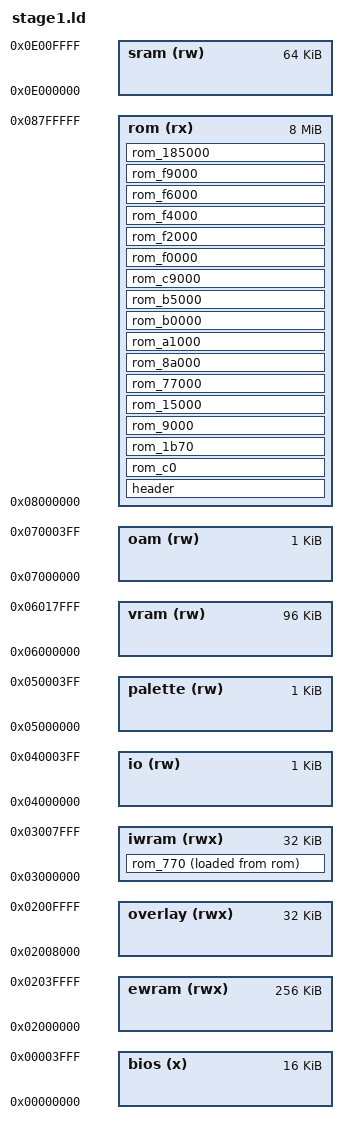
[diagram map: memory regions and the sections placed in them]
MEMORY {
	bios	(x)	: ORIGIN = 0x00000000, LENGTH = 16K
	ewram	(rwx)	: ORIGIN = 0x02000000, LENGTH = 256K
	overlay (rwx)	: ORIGIN = 0x02008000, LENGTH = 32K
	iwram	(rwx)	: ORIGIN = 0x03000000, LENGTH = 32K
	io	(rw)	: ORIGIN = 0x04000000, LENGTH = 1K
	palette	(rw)	: ORIGIN = 0x05000000, LENGTH = 1K
	vram	(rw)	: ORIGIN = 0x06000000, LENGTH = 96K
	oam	(rw)	: ORIGIN = 0x07000000, LENGTH = 1K
	rom	(rx)	: ORIGIN = 0x08000000, LENGTH = 8M
	sram	(rw)	: ORIGIN = 0x0E000000, LENGTH = 64K
}

INCLUDE "linker/symbols/wram.sym"
INCLUDE "linker/symbols/message.sym"
INCLUDE "linker/symbols/file_table.sym"
INCLUDE "linker/symbols/event.sym"

SECTIONS {
	header : {
		build/usa/obj/src/core/header/rom_header.o(.text)
	} > rom

	rom_c0 : {
		build/usa/obj/exports/core/startup/exports.o(.text)
		build/usa/obj/src/core/startup/crt0.o(.text)
	} > rom

	rom_770 : {
		build/usa/obj/src/core/ramlib.o(.text)
	} > iwram AT > rom

	rom_1b70 : {
		build/usa/obj/src/core/runtime/decompress/lz1.o(.text)
		build/usa/obj/src/core/runtime/render/blit_fade_rom.o(.text)
		build/usa/obj/src/core/runtime/render/blit_fade_alt.o(.text)
		build/usa/obj/src/core/runtime/decompress/lz16.o(.text)
		build/usa/obj/src/core/runtime/math/gcc_div.o(.text)
		build/usa/obj/src/core/runtime/math/sin.o(.text)
		build/usa/obj/src/core/runtime/decompress/lz_rom.o(.text)
		build/usa/obj/src/core/runtime/decompress/lz2.o(.text)
		build/usa/obj/src/core/runtime/fixup_ram_code.o(.text)
		build/usa/obj/src/core/runtime/memory/free.o(.text)
		build/usa/obj/src/core/runtime/main.o(.text)
		build/usa/obj/src/core/runtime/intr/intr.o(.text)
		build/usa/obj/src/core/runtime/video.o(.text)
		build/usa/obj/src/core/runtime/task.o(.text)
		build/usa/obj/src/core/runtime/random.o(.text)
		build/usa/obj/src/core/runtime/math/math.o(.text)
		build/usa/obj/src/core/runtime/sprite/palette.o(.text)
		build/usa/obj/src/core/runtime/memory/alloc.o(.text)
		build/usa/obj/src/core/runtime/math/matrix.o(.text)
		build/usa/obj/src/core/runtime/math/vector.o(.text)
		build/usa/obj/src/core/runtime/decompress/lz.o(.text)
		build/usa/obj/src/core/runtime/render/blit_fade.o(.text)
		build/usa/obj/src/core/runtime/save.o(.text)
		build/usa/obj/src/core/runtime/serial.o(.text)
		build/usa/obj/src/core/runtime/other/sub_8006864.o(.text)
		build/usa/obj/src/lib/agb_flash/agb_flash.o(.text)
		build/usa/obj/src/lib/agb_flash/agb_flash_mx.o(.text)
		build/usa/obj/src/lib/agb_flash/agb_flash_verify.o(.text)
		build/usa/obj/src/lib/agb_flash/agb_flash_at.o(.text)
		build/usa/obj/src/lib/call_via.o(.text)

		build/usa/obj/src/core/runtime/intr/intr.o(.rodata)
		build/usa/obj/data/core/runtime/rom_45e8_c_c_c_c_c.o(.rodata)
		build/usa/obj/data/core/runtime/rom_49a8_c_c_c_c_c.o(.rodata)
		build/usa/obj/src/core/runtime/save.o(.rodata)
		build/usa/obj/src/lib/agb_flash/agb_flash_data.o(.rodata)

		. += 0x1000;
	} > rom

	rom_9000 : ALIGN(0x1000) {
		build/usa/obj/exports/field_engine/exports.o(.text)
		build/usa/obj/src/field_engine/sprite/draw_sprite.o(.text)
		build/usa/obj/src/field_engine/engine/unpack_tilemap.o(.text)
		build/usa/obj/src/field_engine/sprite/rom_a418.o(.text)
		build/usa/obj/src/field_engine/decompress/sprite_lz.o(.text)
		build/usa/obj/src/field_engine/sprite/sprite.o(.text)
		build/usa/obj/src/field_engine/actor/actor.o(.text)
		build/usa/obj/src/field_engine/actor/actor_script.o(.text)
		build/usa/obj/src/field_engine/actor/player.o(.text)
		build/usa/obj/src/field_engine/field/map_data.o(.text)
		build/usa/obj/src/field_engine/engine/sprite_test.o(.text)

		build/usa/obj/src/field_engine/sprite/sprite.o(.rodata.rom_b798_c_c)
		build/usa/obj/src/field_engine/sprite/sprite.o(.rodata.rom_b074_c)
		build/usa/obj/src/field_engine/sprite/sprite.o(.rodata)
		build/usa/obj/src/field_engine/sprite/sprite.o(.rodata.rom_be70_c)
		build/usa/obj/src/field_engine/actor/actor.o(.rodata)
		build/usa/obj/src/field_engine/actor/actor_script.o(.rodata)
		build/usa/obj/data/field_engine/rom_d654_c_c_c.o(.rodata)
		build/usa/obj/src/field_engine/actor/player.o(.rodata)
		build/usa/obj/src/field_engine/field/map_data.o(.rodata.rom_108e4)
		build/usa/obj/src/field_engine/field/map_data.o(.rodata.rom_11ce0_c_c)
		build/usa/obj/src/field_engine/engine/sprite_test.o(.rodata.rom_1219c_c_c)
		build/usa/obj/data/field_engine/rom_c004_c_c_c.o(.rodata)
		build/usa/obj/data/field_engine/rom_13624.o(.rodata)
		build/usa/obj/src/field_engine/field/map_data.o(.rodata.rom_f9cc_c)
	} > rom

	rom_15000 : ALIGN(0x1000) {
		build/usa/obj/exports/ui/exports.o(.text)
		build/usa/obj/src/ui/decompress/huffman.o(.text)
		build/usa/obj/src/ui/decompress/icon.o(.text)
		build/usa/obj/src/ui/window.o(.text)
		build/usa/obj/src/ui/ui.o(.text)
		build/usa/obj/src/ui/icon.o(.text)
		build/usa/obj/src/ui/menu.o(.text)
		build/usa/obj/src/ui/text.o(.text)
		build/usa/obj/src/ui/save_menu.o(.text)
		build/usa/obj/src/ui/menus/menu_bars.o(.text)
		build/usa/obj/src/ui/menus/debug_warp_menu.o(.text)
		build/usa/obj/src/ui/menus/debug_flag_editor.o(.text)
		build/usa/obj/src/ui/debug/icon_test.o(.text)

		build/usa/obj/data/ui/rom_29910.o(.rodata)
		build/usa/obj/src/ui/icon.o(.rodata)
		build/usa/obj/data/ui/rom_310a4.o(.rodata)
		build/usa/obj/src/ui/save_menu.o(.rodata.rom_22a7c)
		build/usa/obj/data/ui/rom_317e4.o(.rodata)
		build/usa/obj/src/ui/ui.o(.rodata.rom_178b0)
		build/usa/obj/data/ui/rom_32224.o(.rodata)
		build/usa/obj/src/ui/ui.o(.rodata.rom_17e88_c)
		build/usa/obj/src/ui/ui.o(.rodata.rom_1908c_c_c)
		build/usa/obj/src/ui/menu.o(.rodata.rom_1aeec_c_c)
		build/usa/obj/data/ui/rom_346f8.o(.rodata)
		build/usa/obj/src/ui/menu.o(.rodata.rom_1a66c_c_c)
		build/usa/obj/src/ui/menu.o(.rodata.rom_1ca1c_c_c_c)
		build/usa/obj/data/ui/rom_367e4.o(.rodata)
		build/usa/obj/src/ui/text.o(.rodata)
		build/usa/obj/src/ui/save_menu.o(.rodata.rom_20198_c_c_c_c_c)
		build/usa/obj/src/ui/save_menu.o(.rodata.rom_23178_c_c)
		build/usa/obj/generated/strings/strings.o(.rodata)
		build/usa/obj/data/ui/rom_15e8c_c_c_c.o(.rodata)
		build/usa/obj/data/ui/rom_73812.o(.rodata)
		build/usa/obj/src/ui/save_menu.o(.rodata.rom_1fe2c)
		build/usa/obj/data/ui/rom_73864.o(.rodata)

		. += 0x3000;
	} > rom

	rom_77000 : ALIGN(0x1000) {
		build/usa/obj/exports/rpg/exports.o(.text)
		build/usa/obj/src/rpg/party.o(.text)
		build/usa/obj/src/rpg/get_unit.o(.text)
		build/usa/obj/src/rpg/party.o(.text.party_2)
		build/usa/obj/src/rpg/item.o(.text)
		build/usa/obj/src/rpg/move.o(.text)
		build/usa/obj/src/rpg/pc.o(.text)
		build/usa/obj/src/rpg/flags.o(.text)
		build/usa/obj/src/rpg/pc.o(.text.rpg_pc_2)
		build/usa/obj/src/rpg/summon.o(.text)
		build/usa/obj/src/rpg/random.o(.text)
		build/usa/obj/src/rpg/pc.o(.text.rpg_pc_3)
		build/usa/obj/src/rpg/djinni.o(.text)
		build/usa/obj/src/rpg/pc.o(.text.rpg_pc_4)

		build/usa/obj/src/rpg/party.o(.rodata)
		build/usa/obj/data/rpg/rom_79008_c.o(.rodata)
		build/usa/obj/data/rpg/rom_78a8c_c_c.o(.rodata)
		build/usa/obj/data/rpg/rom_78ee8_c.o(.rodata)
		build/usa/obj/data/rpg/rom_78414_c_c_c_c.o(.rodata)
		build/usa/obj/data/rpg/rom_78b9c_c.o(.rodata)
		build/usa/obj/data/rpg/rom_80ec8.o(.rodata)
		build/usa/obj/data/rpg/rom_78ed8_c.o(.rodata)
		build/usa/obj/src/rpg/djinni.o(.rodata)
	} > rom

	rom_8a000 : ALIGN(0x1000) {
		build/usa/obj/exports/field/exports.o(.text)
		build/usa/obj/src/field/map_load.o(.text)
		build/usa/obj/src/field/room_load.o(.text)
		build/usa/obj/src/field/map_actor.o(.text)
		build/usa/obj/src/field/field.o(.text)
		build/usa/obj/src/field/map.o(.text)
		build/usa/obj/src/field/cutscene.o(.text)
		build/usa/obj/src/field/map_actor.o(.text.map_actor_2)
		build/usa/obj/src/field/map_actor_api.o(.text)
		build/usa/obj/src/field/weather.o(.text)
		build/usa/obj/src/field/djinni.o(.text)
		build/usa/obj/src/field/field_move.o(.text)
		build/usa/obj/src/field/weather.o(.text.weather_2)
		build/usa/obj/src/field/actor_move.o(.text)
		build/usa/obj/src/field/psynergy.o(.text)
		build/usa/obj/src/field/moves/mind_read.o(.text)
		build/usa/obj/src/field/psynergy.o(.text.psynergy_2)
		build/usa/obj/src/field/moves/move.o(.text)
		build/usa/obj/src/field/moves/reveal.o(.text)
		build/usa/obj/src/field/moves/growth.o(.text)
		build/usa/obj/src/field/moves/lift.o(.text)
		build/usa/obj/src/field/moves/force.o(.text)
		build/usa/obj/src/field/moves/frost.o(.text)
		build/usa/obj/src/field/moves/ply.o(.text)
		build/usa/obj/src/field/moves/cloak.o(.text)
		build/usa/obj/src/field/moves/douse.o(.text)
		build/usa/obj/src/field/moves/carry.o(.text)
		build/usa/obj/src/field/moves/whirlwind.o(.text)
		build/usa/obj/src/field/moves/halt.o(.text)
		build/usa/obj/src/field/moves/catch.o(.text)
		build/usa/obj/src/field/moves/retreat.o(.text)
		build/usa/obj/src/field/moves/avoid.o(.text)
		build/usa/obj/src/field/field_effect.o(.text)
		build/usa/obj/src/field/transition.o(.text)

		build/usa/obj/src/field/actor_move.o(.rodata)
		build/usa/obj/src/field/field_effect.o(.rodata)
		build/usa/obj/data/field/rom_8ace0_c.o(.rodata)
		build/usa/obj/src/field/map.o(.rodata)
		build/usa/obj/data/field/rom_9259c_c.o(.rodata)
		build/usa/obj/src/field/map_actor.o(.rodata.rom_92950_c_c_c_c)
		build/usa/obj/src/field/weather.o(.rodata)
		build/usa/obj/data/field/rom_9f0b0.o(.rodata)
		build/usa/obj/src/field/moves/move.o(.rodata)
		build/usa/obj/src/field/moves/avoid.o(.rodata)
		build/usa/obj/data/field/rom_9bb64_c_c.o(.rodata)
		build/usa/obj/data/field/rom_8a5f8_c.o(.rodata)
		build/usa/obj/data/field/rom_8b674_c_c_c.o(.rodata)
		build/usa/obj/data/field/rom_9f840.o(.rodata)
		build/usa/obj/data/field/rom_91584_c_c_c_c.o(.rodata)
		build/usa/obj/data/field/rom_925e0_c.o(.rodata)
		build/usa/obj/data/field/rom_9fc1c.o(.rodata)
		build/usa/obj/src/field/map_actor_api.o(.rodata.rom_93304_c_c_c)
		build/usa/obj/data/field/rom_9ff40.o(.rodata)
		build/usa/obj/src/field/psynergy.o(.rodata)
		build/usa/obj/src/field/moves/halt.o(.rodata)
		build/usa/obj/data/field/rom_a0138.o(.rodata)
	} > rom

	rom_a1000 : ALIGN(0x1000) {
		build/usa/obj/exports/party_menu/exports.o(.text)
		build/usa/obj/src/party_menu/party_menu.o(.text)

		build/usa/obj/data/party_menu/rom_a172c_c.o(.rodata)
		build/usa/obj/src/party_menu/party_menu.o(.rodata.rom_a5534_c_c_c)
		build/usa/obj/src/party_menu/party_menu.o(.rodata.rom_ae88c_c_c_c)
		build/usa/obj/src/party_menu/party_menu.o(.rodata.rom_a4f08)
		build/usa/obj/src/party_menu/party_menu.o(.rodata.rom_a1050_c_c_c)
		build/usa/obj/data/party_menu/rom_a47b4_c_c_c_c_c_c.o(.rodata)
		build/usa/obj/data/party_menu/rom_a8604_c_c_c_c_c.o(.rodata)
		build/usa/obj/data/party_menu/rom_af26c.o(.rodata)
		build/usa/obj/src/party_menu/party_menu.o(.rodata.rom_aa538_c_c_c)
		build/usa/obj/src/party_menu/party_menu.o(.rodata.rom_a1814_c_c_c)
		build/usa/obj/src/party_menu/party_menu.o(.rodata.rom_a7380)
		build/usa/obj/src/party_menu/party_menu.o(.rodata.rom_ad274_c_c)
	} > rom

	rom_b0000 : ALIGN(0x1000) {
		build/usa/obj/exports/shop/exports.o(.text)
		build/usa/obj/src/shop/shop.o(.text)

		build/usa/obj/src/shop/shop.o(.rodata)
	} > rom

	rom_b5000 : ALIGN(0x1000) {
		build/usa/obj/exports/battle/exports.o(.text)
		build/usa/obj/src/battle/decompress/battle_bg.o(.text)
		build/usa/obj/src/battle/debug_battle_test.o(.text)
		build/usa/obj/src/battle/battle.o(.text)
		build/usa/obj/src/battle/mechanics.o(.text)
		build/usa/obj/src/battle/battle_anim/transition_in.o(.text)
		build/usa/obj/src/battle/mechanics.o(.text.mechanics_2)
		build/usa/obj/src/battle/battle_anim/cast.o(.text)
		build/usa/obj/src/battle/battle_anim/move_intro.o(.text)
		build/usa/obj/src/battle/battle_anim/cast.o(.text.cast_2)
		build/usa/obj/src/battle/enemy.o(.text)

		build/usa/obj/data/battle/rom_c2a0c.o(.rodata)
		build/usa/obj/src/battle/battle.o(.rodata.rom_b5a0c_c_c_c)
		build/usa/obj/src/battle/battle.o(.rodata.rom_b6eb4)
		build/usa/obj/data/battle/rom_b7410_c_c_c_c_c.o(.rodata)
		build/usa/obj/src/battle/mechanics.o(.rodata.rom_bbb0c_c)
		build/usa/obj/data/battle/rom_c10e8_c.o(.rodata)
		build/usa/obj/data/battle/rom_c3734.o(.rodata)
		build/usa/obj/src/battle/debug_battle_test.o(.rodata)
		build/usa/obj/src/battle/battle.o(.rodata.rom_b6f44)
		build/usa/obj/src/battle/battle.o(.rodata.rom_b6e7c)
		build/usa/obj/data/battle/rom_b8228_c_c.o(.rodata)
		build/usa/obj/src/battle/mechanics.o(.rodata.rom_bffb8_c_c)
		build/usa/obj/data/battle/rom_c1a34_c.o(.rodata)

		. += 0x1000;
	} > rom

	rom_c9000 : ALIGN(0x1000) {
		build/usa/obj/exports/battle_anim/exports.o(.text)
		build/usa/obj/src/battle_anim/render/window_effect.o(.text)
		build/usa/obj/src/battle_anim/moves/ice.o(.text)
		build/usa/obj/src/battle_anim/moves/douse.o(.text)
		build/usa/obj/src/battle_anim/moves/sonic_wave.o(.text)
		build/usa/obj/src/battle_anim/moves/spore.o(.text)
		build/usa/obj/src/battle_anim/moves/bite_sting.o(.text)
		build/usa/obj/src/battle_anim/moves/death_plunge.o(.text)
		build/usa/obj/src/battle_anim/moves/unused_sabre_rain.o(.text)
		build/usa/obj/src/battle_anim/epower_up.o(.text)
		build/usa/obj/src/battle_anim/screen_shatter.o(.text)
		build/usa/obj/src/battle_anim/djinn_set.o(.text)
		build/usa/obj/src/battle_anim/unleash_intro.o(.text)
		build/usa/obj/src/battle_anim/moves/tentacle.o(.text)
		build/usa/obj/src/battle_anim/moves/spider_web.o(.text)
		build/usa/obj/src/battle_anim/transition_out.o(.text)
		build/usa/obj/src/battle_anim/anim_util.o(.text)
		build/usa/obj/src/battle_anim/moves/planet_diver.o(.text)
		build/usa/obj/src/battle_anim/moves/haunt.o(.text)
		build/usa/obj/src/battle_anim/moves/confuse.o(.text)
		build/usa/obj/src/battle_anim/moves/haunt_attack.o(.text)
		build/usa/obj/src/battle_anim/render/draw2D_util.o(.text)
		build/usa/obj/src/battle_anim/moves/spasm.o(.text)
		build/usa/obj/src/battle_anim/moves/revive.o(.text)
		build/usa/obj/src/battle_anim/moves/mud.o(.text)
		build/usa/obj/src/battle_anim/moves/condemn.o(.text)
		build/usa/obj/src/battle_anim/unused_screen_melt.o(.text)
		build/usa/obj/src/battle_anim/moves/bind.o(.text)
		build/usa/obj/src/battle_anim/moves/psyphon_seal.o(.text)
		build/usa/obj/src/battle_anim/moves/astral_blast.o(.text)
		build/usa/obj/src/battle_anim/moves/shining_star.o(.text)
		build/usa/obj/src/battle_anim/moves/procne.o(.text)
		build/usa/obj/src/battle_anim/moves/tiamat.o(.text)
		build/usa/obj/src/battle_anim/moves/nereid.o(.text)
		build/usa/obj/src/battle_anim/moves/froth.o(.text)
		build/usa/obj/src/battle_anim/moves/whirlwind.o(.text)
		build/usa/obj/src/battle_anim/moves/prism.o(.text)
		build/usa/obj/src/battle_anim/color_cycle_vfx_palette.o(.text)
		build/usa/obj/src/battle_anim/moves/plasma.o(.text)
		build/usa/obj/src/battle_anim/moves/nova.o(.text)
		build/usa/obj/src/battle_anim/moves/volcano.o(.text)
		build/usa/obj/src/battle_anim/moves/particle_cloud.o(.text)
		build/usa/obj/src/battle_anim/moves/sleep.o(.text)
		build/usa/obj/src/battle_anim/moves/curse.o(.text)
		build/usa/obj/src/battle_anim/moves/unused_fizz.o(.text)
		build/usa/obj/src/battle_anim/camera.o(.text)
		build/usa/obj/src/battle_anim/anims.o(.text)
		build/usa/obj/src/battle_anim/camera.o(.text.camera_2)
		build/usa/obj/src/battle_anim/moves/cybele.o(.text)
		build/usa/obj/src/battle_anim/moves/boreas.o(.text)
		build/usa/obj/src/battle_anim/moves/break.o(.text)
		build/usa/obj/src/battle_anim/moves/drain.o(.text)
		build/usa/obj/src/battle_anim/moves/heal.o(.text)
		build/usa/obj/src/battle_anim/moves/stat_up.o(.text)
		build/usa/obj/src/battle_anim/moves/stat_down.o(.text)
		build/usa/obj/src/battle_anim/moves/flare.o(.text)
		build/usa/obj/src/battle_anim/moves/quake.o(.text)
		build/usa/obj/src/battle_anim/moves/fireball.o(.text)
		build/usa/obj/src/battle_anim/moves/frost.o(.text)
		build/usa/obj/src/battle_anim/moves/ray.o(.text)
		build/usa/obj/src/battle_anim/moves/blast.o(.text)
		build/usa/obj/src/battle_anim/sprite/summon.o(.text)
		build/usa/obj/src/battle_anim/moves/breath.o(.text)
		build/usa/obj/src/battle_anim/unused_element_orbs.o(.text)
		build/usa/obj/src/battle_anim/moves/unused_skull_spin.o(.text)
		build/usa/obj/src/battle_anim/moves/unused_skull_cloud.o(.text)
		build/usa/obj/src/battle_anim/moves/atalanta.o(.text)
		build/usa/obj/src/battle_anim/moves/growth.o(.text)
		build/usa/obj/src/battle_anim/moves/vine.o(.text)
		build/usa/obj/src/battle_anim/moves/thorn.o(.text)
		build/usa/obj/src/battle_anim/moves/bolt.o(.text)
		build/usa/obj/src/battle_anim/djinni.o(.text)
		build/usa/obj/src/battle_anim/moves/projectile.o(.text)
		build/usa/obj/src/battle_anim/moves/tackle.o(.text)
		build/usa/obj/src/battle_anim/moves/mercury.o(.text)
		build/usa/obj/src/battle_anim/moves/jupiter.o(.text)
		build/usa/obj/src/battle_anim/vfx.o(.text)
		build/usa/obj/src/battle_anim/moves/venus.o(.text)
		build/usa/obj/src/battle_anim/moves/mars.o(.text)
		build/usa/obj/src/battle_anim/moves/hail.o(.text)
		build/usa/obj/src/battle_anim/moves/ground.o(.text)
		build/usa/obj/src/battle_anim/update_screen_shake.o(.text)
		build/usa/obj/src/battle_anim/moves/thor.o(.text)
		build/usa/obj/src/battle_anim/moves/spire.o(.text)
		build/usa/obj/src/battle_anim/moves/rapid_slash.o(.text)
		build/usa/obj/src/battle_anim/moves/gaia.o(.text)
		build/usa/obj/src/battle_anim/moves/rapid_slash.o(.text.rapid_slash_2)
		build/usa/obj/src/battle_anim/battle/actor_pos.o(.text)
		build/usa/obj/src/battle_anim/attack.o(.text)
		build/usa/obj/src/battle_anim/battle/actor_pos.o(.text.actor_pos_2)
		build/usa/obj/src/battle_anim/special_attack.o(.text)
		build/usa/obj/src/battle_anim/moves/torch.o(.text)
		build/usa/obj/src/battle_anim/moves/kite.o(.text)
		build/usa/obj/src/battle_anim/moves/helm_splitter.o(.text)
		build/usa/obj/src/battle_anim/summon_sprite.o(.text)
		build/usa/obj/src/battle_anim/moves/meteor.o(.text)
		build/usa/obj/src/battle_anim/moves/ramses.o(.text)
		build/usa/obj/src/battle_anim/moves/dragon_cloud.o(.text)
		build/usa/obj/src/battle_anim/moves/annihilation.o(.text)
		build/usa/obj/src/battle_anim/moves/ragnarok.o(.text)
		build/usa/obj/src/battle_anim/moves/titan_blade.o(.text)
		build/usa/obj/src/battle_anim/moves/judgment.o(.text)
		build/usa/obj/src/battle_anim/moves/kirin.o(.text)
		build/usa/obj/src/battle_anim/moves/neptune.o(.text)
		build/usa/obj/src/battle_anim/moves/thrash.o(.text)
		build/usa/obj/src/battle_anim/moves/fullscreen_slash.o(.text)
		build/usa/obj/src/battle_anim/moves/undead_sword.o(.text)
		build/usa/obj/src/battle_anim/render/draw2D.o(.text)

		build/usa/obj/data/battle_anim/rom_eda78.o(.rodata)
		build/usa/obj/src/battle_anim/moves/sonic_wave.o(.rodata)
		build/usa/obj/src/battle_anim/moves/bite_sting.o(.rodata)
		build/usa/obj/src/battle_anim/moves/death_plunge.o(.rodata)
		build/usa/obj/src/battle_anim/moves/unused_sabre_rain.o(.rodata)
		build/usa/obj/src/battle_anim/screen_shatter.o(.rodata)
		build/usa/obj/src/battle_anim/djinn_set.o(.rodata)
		build/usa/obj/src/battle_anim/moves/haunt_attack.o(.rodata)
		build/usa/obj/src/battle_anim/moves/spasm.o(.rodata)
		build/usa/obj/src/battle_anim/moves/revive.o(.rodata)
		build/usa/obj/src/battle_anim/moves/mud.o(.rodata)
		build/usa/obj/src/battle_anim/moves/condemn.o(.rodata)
		build/usa/obj/src/battle_anim/moves/bind.o(.rodata)
		build/usa/obj/src/battle_anim/moves/psyphon_seal.o(.rodata)
		build/usa/obj/src/battle_anim/moves/astral_blast.o(.rodata)
		build/usa/obj/src/battle_anim/moves/shining_star.o(.rodata)
		build/usa/obj/src/battle_anim/moves/procne.o(.rodata)
		build/usa/obj/src/battle_anim/moves/tiamat.o(.rodata)
		build/usa/obj/src/battle_anim/moves/nereid.o(.rodata)
		build/usa/obj/src/battle_anim/moves/froth.o(.rodata)
		build/usa/obj/src/battle_anim/moves/whirlwind.o(.rodata)
		build/usa/obj/src/battle_anim/moves/prism.o(.rodata)
		build/usa/obj/src/battle_anim/moves/plasma.o(.rodata)
		build/usa/obj/src/battle_anim/moves/nova.o(.rodata)
		build/usa/obj/src/battle_anim/moves/volcano.o(.rodata)
		build/usa/obj/src/battle_anim/moves/particle_cloud.o(.rodata)
		build/usa/obj/data/battle_anim/rom_ee2b4.o(.rodata)
		build/usa/obj/src/battle_anim/moves/cybele.o(.rodata)
		build/usa/obj/src/battle_anim/moves/boreas.o(.rodata)
		build/usa/obj/src/battle_anim/moves/break.o(.rodata)
		build/usa/obj/src/battle_anim/moves/stat_down.o(.rodata)
		build/usa/obj/src/battle_anim/moves/quake.o(.rodata)
		build/usa/obj/src/battle_anim/moves/fireball.o(.rodata)
		build/usa/obj/src/battle_anim/moves/frost.o(.rodata)
		build/usa/obj/src/battle_anim/moves/ray.o(.rodata)
		build/usa/obj/src/battle_anim/moves/blast.o(.rodata)
		build/usa/obj/src/battle_anim/moves/breath.o(.rodata)
		build/usa/obj/src/battle_anim/moves/atalanta.o(.rodata)
		build/usa/obj/src/battle_anim/moves/growth.o(.rodata)
		build/usa/obj/src/battle_anim/moves/vine.o(.rodata)
		build/usa/obj/src/battle_anim/moves/thorn.o(.rodata)
		build/usa/obj/src/battle_anim/moves/bolt.o(.rodata)
		build/usa/obj/src/battle_anim/moves/projectile.o(.rodata)
		build/usa/obj/src/battle_anim/moves/tackle.o(.rodata)
		build/usa/obj/src/battle_anim/moves/mercury.o(.rodata)
		build/usa/obj/src/battle_anim/moves/venus.o(.rodata)
		build/usa/obj/src/battle_anim/moves/hail.o(.rodata)
		build/usa/obj/src/battle_anim/moves/ground.o(.rodata)
		build/usa/obj/src/battle_anim/moves/thor.o(.rodata)
		build/usa/obj/src/battle_anim/moves/spire.o(.rodata)
		build/usa/obj/data/battle_anim/rom_e28f4_c_c_c.o(.rodata)
		build/usa/obj/src/battle_anim/battle/actor_pos.o(.rodata)
		build/usa/obj/src/battle_anim/special_attack.o(.rodata)
		build/usa/obj/data/battle_anim/rom_e6638_c.o(.rodata)
		build/usa/obj/src/battle_anim/moves/meteor.o(.rodata)
		build/usa/obj/src/battle_anim/moves/ramses.o(.rodata)
		build/usa/obj/src/battle_anim/moves/ragnarok.o(.rodata)
		build/usa/obj/src/battle_anim/moves/titan_blade.o(.rodata)
		build/usa/obj/src/battle_anim/moves/judgment.o(.rodata)
		build/usa/obj/src/battle_anim/moves/neptune.o(.rodata)
		build/usa/obj/src/battle_anim/moves/thrash.o(.rodata)
		build/usa/obj/src/battle_anim/moves/undead_sword.o(.rodata)
		build/usa/obj/src/battle_anim/render/draw2D.o(.rodata)
	} > rom

	rom_f0000 : ALIGN(0x1000) {
		build/usa/obj/exports/ending/exports.o(.text)
		build/usa/obj/src/ending/other/sub_80f0008.o(.text)
		build/usa/obj/src/ending/decompress/bg-credits.o(.text)
		build/usa/obj/src/ending/ending.o(.text)

		build/usa/obj/src/ending/ending.o(.rodata)
	} > rom

	rom_f2000 : ALIGN(0x1000) {
		build/usa/obj/exports/title/exports.o(.text)
		build/usa/obj/src/title/title.o(.text)

		build/usa/obj/data/title/rom_f2028_c_c_c_c.o(.rodata)
	} > rom

	rom_f4000 : ALIGN(0x1000) {
		build/usa/obj/exports/lucky_dice/exports.o(.text)
		build/usa/obj/src/lucky_dice/lucky_dice.o(.text)

		build/usa/obj/src/lucky_dice/lucky_dice.o(.rodata)
	} > rom

	rom_f6000 : ALIGN(0x1000) {
		build/usa/obj/exports/lucky_wheels/exports.o(.text)
		build/usa/obj/src/lucky_wheels/lucky_wheels.o(.text)

		build/usa/obj/src/lucky_wheels/lucky_wheels.o(.rodata)
	} > rom

	rom_f9000 : ALIGN(0x1000) {
		build/usa/obj/exports/sound/exports.o(.text)
		build/usa/obj/src/sound/sound.o(.text)
		build/usa/obj/src/sound/other/sub_80f95e0.o(.text)
		build/usa/obj/src/lib/m4a/m4a.o(.text)

		build/usa/obj/data/sound/rom_f9080_c_c_c_c.o(.rodata)
		build/usa/obj/src/sound/other/sub_80f95e0.o(.rodata)
		build/usa/obj/data/sound/rom_f9ef8_c_c_c.o(.rodata)
		build/usa/obj/data/sound/rom_fc624.o(.rodata)
	} > rom

	rom_185000 : ALIGN(0x1000) {
		build/usa/obj/exports/sprite_info/exports.o(.text)
		build/usa/obj/src/sprite_info/sprite_info.o(.text)

		build/usa/obj/data/sprite_info/rom_185008_c.o(.rodata)

		. += 0x1000;
	} > rom

	/DISCARD/ : {
		*(*)
	}
}
